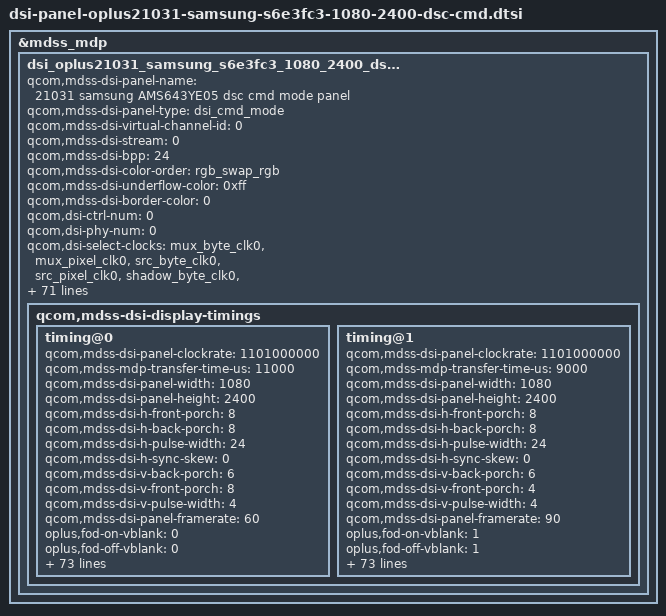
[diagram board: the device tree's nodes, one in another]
&mdss_mdp {
	dsi_oplus21031_samsung_s6e3fc3_1080_2400_dsc_cmd: qcom,mdss_dsi_oplus21031_samsung_s6e3fc3_1080_2400_dsc_cmd {
		qcom,mdss-dsi-panel-name =
		  "21031 samsung AMS643YE05 dsc cmd mode panel";
		qcom,mdss-dsi-panel-type = "dsi_cmd_mode";
		qcom,mdss-dsi-virtual-channel-id = <0>;
		qcom,mdss-dsi-stream = <0>;
		qcom,mdss-dsi-bpp = <24>;
		qcom,mdss-dsi-color-order = "rgb_swap_rgb";
		qcom,mdss-dsi-underflow-color = <0xff>;
		qcom,mdss-dsi-border-color = <0>;

		qcom,dsi-ctrl-num = <0>;
		qcom,dsi-phy-num = <0>;
		qcom,dsi-select-clocks = "src_byte_clk0", "src_pixel_clk0";

		qcom,mdss-dsi-traffic-mode = "non_burst_sync_event";
		qcom,mdss-dsi-lane-map = "lane_map_0123";
		qcom,mdss-dsi-bllp-eof-power-mode;
		qcom,mdss-dsi-bllp-power-mode;
		qcom,mdss-dsi-lane-0-state;
		qcom,mdss-dsi-lane-1-state;
		qcom,mdss-dsi-lane-2-state;
		qcom,mdss-dsi-lane-3-state;
		qcom,mdss-dsi-dma-trigger = "trigger_sw";
		qcom,mdss-dsi-mdp-trigger = "none";
		qcom,mdss-dsi-reset-sequence = <1 10>, <0 10>, <1 10>;
		qcom,mdss-dsi-te-pin-select = <1>;
		qcom,mdss-dsi-te-dcs-command = <1>;
		qcom,mdss-dsi-te-check-enable;
		qcom,mdss-dsi-te-using-te-pin;
		qcom,mdss-dsi-wr-mem-start = <0x2c>;
		qcom,mdss-dsi-wr-mem-continue = <0x3c>;
		qcom,mdss-dsi-panel-hdr-enabled;
		qcom,mdss-dsi-panel-hdr-color-primaries = <15000 15500 34000
			16000 13250 34500 7500 3000>;
		qcom,mdss-dsi-panel-peak-brightness = <4300000>;
		qcom,mdss-dsi-panel-blackness-level = <1023>;
		qcom,mdss-pan-physical-width-dimension = <68>;
		qcom,mdss-pan-physical-height-dimension = <152>;
		qcom,esd-check-enabled;
		qcom,mdss-dsi-panel-status-check-mode = "reg_read";
		qcom,mdss-dsi-panel-status-command = [06 01 00 01 05 00 02 0A 00];
		qcom,mdss-dsi-panel-status-command-state = "dsi_hs_mode";
		qcom,mdss-dsi-panel-status-value = <0x9F>;
		qcom,mdss-dsi-panel-status-read-length = <1>;

		qcom,mdss-dsi-display-timings {
			timing@0{
				qcom,mdss-dsi-panel-clockrate = <1101000000>;
				qcom,mdss-mdp-transfer-time-us = <11000>;
				qcom,mdss-dsi-panel-width = <1080>;
				qcom,mdss-dsi-panel-height = <2400>;
				qcom,mdss-dsi-h-front-porch = <8>;
				qcom,mdss-dsi-h-back-porch = <8>;
				qcom,mdss-dsi-h-pulse-width = <24>;
				qcom,mdss-dsi-h-sync-skew = <0>;
				qcom,mdss-dsi-v-back-porch = <6>;
				qcom,mdss-dsi-v-front-porch = <8>;
				qcom,mdss-dsi-v-pulse-width = <4>;
				qcom,mdss-dsi-panel-framerate = <60>;
				oplus,fod-on-vblank = <0>;
				oplus,fod-off-vblank = <0>;
				/* Apollo vsync config, need to measure TE signal */
				oplus,apollo-panel-vsync-width = <5680>;
				oplus,apollo-panel-vsync-period = <16850>;

				qcom,mdss-dsi-on-command = [
					/* PPS Setting */
					39 01 00 00 00 00 81 9E
						11 00 00 89 30 80 09 60
						04 38 00 1E 02 1C 02 1C
						02 00 02 0E 00 20 02 E3
						00 07 00 0C 03 50 03 64
						18 00 10 F0 03 0C 20 00
						06 0B 0B 33 0E 1C 2A 38
						46 54 62 69 70 77 79 7B
						7D 7E 01 02 01 00 09 40
						09 BE 19 FC 19 FA 19 F8
						1A 38 1A 78 1A B6 2A F6
						2B 34 2B 74 3B 74 6B F4
						00 00 00 00 00 00 00 00
						00 00 00 00 00 00 00 00
						00 00 00 00 00 00 00 00
						00 00 00 00 00 00 00 00
						00 00 00 00 00 00 00 00
					15 01 00 00 00 00 02 C2 14
					15 01 00 00 00 00 02 9D 01
					/* Display On Setting */
					05 01 00 00 78 00 01 11
					/* TE vsync ON */
					15 01 00 00 00 00 02 35 00
					/* CASET/PASET Setting */
					39 01 00 00 00 00 05 2A 00 00 04 37
					39 01 00 00 00 00 05 2B 00 00 09 5F
					/* FQ CON Setting*/
					39 00 00 00 00 00 03 F0 5A 5A
					39 00 00 00 00 00 03 B0 27 F2
					15 00 00 00 00 00 02 F2 00
					39 01 00 00 00 00 03 F0 A5 A5
					/* Freuency Setting */
					39 00 00 00 00 00 03 F0 5A 5A
					39 00 00 00 00 00 03 60 00 00	// 60Hz
					15 00 00 00 00 00 02 F7 0F
					39 01 00 00 00 00 03 F0 A5 A5
					/* FFC Setting: OSC 167MHz */
					39 00 00 00 00 00 03 F0 5A 5A
					39 00 00 00 00 00 03 FC 5A 5A
					39 00 00 00 00 00 03 B0 66 C5
					39 00 00 00 00 00 03 C5 00 8C
					39 00 00 00 00 00 03 B0 2A C5
					39 00 00 00 00 00 05 C5 0D 10 80 45
					39 00 00 00 00 00 03 B0 3E C5
					39 00 00 00 00 00 03 C5 4D A6
					39 00 00 00 00 00 03 F0 A5 A5
					39 01 00 00 00 00 03 FC A5 A5
					15 01 00 00 00 00 02 53 20
				];
				qcom,mdss-dsi-post-on-backlight = [
					/* Display On*/
					05 01 00 00 00 00 01 29
				];
				qcom,mdss-dsi-timing-switch-command = [
					/* 60hz Transition */
					39 00 00 00 00 00 03 F0 5A 5A
					39 00 00 00 00 00 03 60 00 00
					39 00 00 00 00 00 02 F7 0F
					39 01 00 00 00 00 03 F0 A5 A5
				];
				qcom,mdss-dsi-off-command = [
					05 01 00 00 0A 00 01 28
					05 01 00 00 78 00 01 10
				];
				qcom,mdss-dsi-lp1-command = [
					05 01 00 00 25 00 01 28
					39 00 00 00 00 00 03 F0 5A 5A
					39 00 00 00 00 00 02 91 01
					15 00 00 00 00 00 02 53 24
					15 00 00 00 00 00 02 BB 1D
					39 01 00 00 00 00 03 F0 A5 A5
				];
				qcom,mdss-dsi-nolp-command = [
					/* AOD CTRL setting */
					39 00 00 00 00 00 03 F0 5A 5A
					39 00 00 00 00 00 05 BB 11 0C 50 10
					39 01 00 00 00 00 03 F0 A5 A5
					/* AOD off */
					39 00 00 00 00 00 03 F0 5A 5A
					39 00 00 00 00 00 02 91 02
					15 00 00 00 00 00 02 53 20
					39 01 00 00 00 00 03 F0 A5 A5
				];
				qcom,mdss-dsi-aod-high-mode-command = [
					15 01 00 00 00 00 02 53 24
				];
				qcom,mdss-dsi-aod-low-mode-command = [
					15 01 00 00 00 00 02 53 24
				];
				qcom,mdss-dsi-aod-hbm-on-command = [
					/* AOD CTRL setting */
					39 00 00 00 00 00 03 F0 5A 5A
					39 00 00 00 00 00 05 BB 11 0C 50 10
					39 01 00 00 00 00 03 F0 A5 A5
					/* AOD off */
					39 00 00 00 00 00 03 F0 5A 5A
					39 00 00 00 00 00 02 91 02
					15 00 00 00 00 00 02 53 20
					39 01 00 00 00 00 03 F0 A5 A5
					/*ELVSS DIMING OFF,DLY OFF*/
					39 00 00 00 00 00 03 F0 5A 5A
					39 00 00 00 00 00 03 B0 91 63
					15 00 00 00 00 00 02 63 20
					39 01 00 00 00 00 03 F0 A5 A5
					/* HBM Mode ON */
					39 00 00 00 00 00 02 53 E0
					39 01 00 00 00 00 03 51 0F FF
				];
				qcom,mdss-dsi-hbm-on-command = [
					/*ELVSS DIMING OFF,DLY OFF*/
					39 00 00 00 00 00 03 F0 5A 5A
					39 00 00 00 00 00 03 B0 91 63
					15 00 00 00 00 00 02 63 20
					39 01 00 00 00 00 03 F0 A5 A5
					39 01 00 00 00 00 02 53 E0
					39 01 00 00 00 00 03 51 0F FF
				];
				qcom,mdss-dsi-normal-hbm-on-command = [
					39 01 00 00 00 00 02 53 E0
					39 01 00 00 00 00 03 51 0F FF
				];
				qcom,mdss-dsi-hbm-off-command = [
					/*ELVSS DIMING OFF,DLY OFF*/
					39 00 00 00 00 00 03 F0 5A 5A
					39 00 00 00 00 00 03 B0 91 63
					15 00 00 00 00 00 02 63 20
					39 01 00 00 00 00 03 F0 A5 A5
					15 01 00 00 00 00 02 53 20
				];
				qcom,mdss-dsi-aod-hbm-off-command = [
					/*HBM OFF */
					15 01 00 00 00 00 02 53 20
					/*AOD on */
					39 00 00 00 00 00 03 F0 5A 5A
					39 00 00 00 00 00 02 91 01
					15 00 00 00 00 00 02 53 24
					15 00 00 00 00 00 02 BB 1D
					39 01 00 00 00 00 03 F0 A5 A5
				];
				qcom,mdss-dsi-seed-off-command = [
					/* CRC OFF */
					39 00 00 00 00 00 03 F0 5A 5A
					15 00 00 00 00 00 02 5D 00
					39 00 00 00 00 00 02 62 01
					39 01 00 00 00 00 03 F0 A5 A5
				];
				qcom,mdss-dsi-seed-0-command = [
					/* SEED CRC Setting */
					39 00 00 00 00 00 03 F0 5A 5A
					39 00 00 00 00 00 02 5D 86
					/* SEED CRC ON */
					39 00 00 00 00 00 02 62 00
					/* SEED CRC DCI-P3 */
					39 00 00 00 00 00 03 B0 2B 62
					39 00 00 00 00 00 16 62 D8 00 04 00 FF 02 00 00 FF 18 FF E4 FB 00 F0 F6 EA 01 FF FF FF
					39 01 00 00 00 00 03 F0 A5 A5
				];
				qcom,mdss-dsi-seed-1-command = [
					/* SEED CRC Setting */
					39 00 00 00 00 00 03 F0 5A 5A
					39 00 00 00 00 00 02 5D 06
					/* SEED CRC ON */
					39 00 00 00 00 00 02 62 00
					/* SEED CRC sRGB */
					39 00 00 00 00 00 03 B0 01 62
					39 00 00 00 00 00 16 62 B0 02 06 3A D7 17 07 05 B2 48 F2 DC C4 07 C8 E9 E9 1D FF FF FF
					39 01 00 00 00 00 03 F0 A5 A5
				];
				qcom,mdss-dsi-seed-2-command = [
					/* SEED CRC Setting */
					39 00 00 00 00 00 03 F0 5A 5A
					39 00 00 00 00 00 02 5D 46
					/* SEED CRC ON */
					39 00 00 00 00 00 02 62 00
					/* SEED CRC Adobe */
					39 00 00 00 00 00 03 B0 16 62
					39 00 00 00 00 00 16 62 D8 00 04 00 FF 02 00 00 FF 18 FF E4 FB 00 F0 F6 EA 01 FF FF FF
					39 01 00 00 00 00 03 F0 A5 A5
				];
				qcom,mdss-dsi-osc-clk-mode0-command = [
					/* OSC 167MHz */
					39 00 00 00 00 00 03 F0 5A 5A
					39 00 00 00 00 00 03 FC 5A 5A
					39 00 00 00 00 00 03 B0 66 C5
					39 00 00 00 00 00 03 C5 00 8C
					39 00 00 00 00 00 03 B0 2A C5
					39 00 00 00 00 00 05 C5 0D 10 80 45
					39 00 00 00 00 00 03 B0 3E C5
					39 00 00 00 00 00 03 C5 4D A6
					39 00 00 00 00 00 03 F0 A5 A5
					39 01 00 00 00 00 03 FC A5 A5
				];
				qcom,mdss-dsi-osc-clk-mode1-command = [
					/* OSC 169MHz */
					39 00 00 00 00 00 03 F0 5A 5A
					39 00 00 00 00 00 03 FC 5A 5A
					39 00 00 00 00 00 03 B0 66 C5
					39 00 00 00 00 00 03 C5 00 8C
					39 00 00 00 00 00 03 B0 2A C5
					39 00 00 00 00 00 05 C5 0D 10 80 45
					39 00 00 00 00 00 03 B0 3E C5
					39 00 00 00 00 00 03 C5 4E 97
					39 00 00 00 00 00 03 F0 A5 A5
					39 01 00 00 00 00 03 FC A5 A5
				];
				qcom,mdss-dsi-hbm-enter-switch-command = [
					39 00 00 00 00 00 03 F0 5A 5A
					39 00 00 00 00 00 03 B0 02 90
					39 00 00 00 00 00 02 90 14
					39 00 00 00 00 00 02 53 E0
					39 01 00 00 00 00 03 F0 A5 A5
				];
				qcom,mdss-dsi-hbm-exit-switch-command = [
					39 00 00 00 00 00 03 F0 5A 5A
					39 00 00 00 00 00 03 B0 02 90
					39 00 00 00 00 00 02 90 1C
					39 00 00 00 00 00 02 53 20
					39 01 00 00 00 00 03 F0 A5 A5
				];
				qcom,mdss-dsi-aod-hbm-on-command-state = "dsi_hs_mode";
				qcom,mdss-dsi-aod-hbm-off-command-state = "dsi_hs_mode";
				qcom,mdss-dsi-seed-off-command-state = "dsi_hs_mode";
				qcom,mdss-dsi-seed-0-command-state = "dsi_hs_mode";
				qcom,mdss-dsi-seed-1-command-state = "dsi_hs_mode";
				qcom,mdss-dsi-seed-2-command-state = "dsi_hs_mode";
				qcom,mdss-dsi-lp1-command-state = "dsi_hs_mode";
				qcom,mdss-dsi-nolp-command-state = "dsi_hs_mode";
				qcom,mdss-dsi-post-on-backlight-state = "dsi_hs_mode";
				qcom,mdss-dsi-on-command-state = "dsi_hs_mode";
				qcom,mdss-dsi-off-command-state = "dsi_hs_mode";
				qcom,compression-mode = "dsc";
				qcom,mdss-dsc-slice-height = <30>;
				qcom,mdss-dsc-slice-width = <540>;
				qcom,mdss-dsc-slice-per-pkt = <2>;
				qcom,mdss-dsc-bit-per-component = <8>;
				qcom,mdss-dsc-bit-per-pixel = <8>;
				qcom,mdss-dsc-block-prediction-enable;
			};

			timing@1{
				qcom,mdss-dsi-panel-clockrate = <1101000000>;
				qcom,mdss-mdp-transfer-time-us = <9000>;
				qcom,mdss-dsi-panel-width = <1080>;
				qcom,mdss-dsi-panel-height = <2400>;
				qcom,mdss-dsi-h-front-porch = <8>;
				qcom,mdss-dsi-h-back-porch = <8>;
				qcom,mdss-dsi-h-pulse-width = <24>;
				qcom,mdss-dsi-h-sync-skew = <0>;
				qcom,mdss-dsi-v-back-porch = <6>;
				qcom,mdss-dsi-v-front-porch = <4>;
				qcom,mdss-dsi-v-pulse-width = <4>;
				qcom,mdss-dsi-panel-framerate = <90>;
				oplus,fod-on-vblank = <1>;
				oplus,fod-off-vblank = <1>;
				/* Apollo vsync config, need to measure TE signal */
				oplus,apollo-panel-vsync-width = <70>;
				oplus,apollo-panel-vsync-period = <11250>;
				qcom,mdss-dsi-on-command = [
					/* PPS Setting */
					39 01 00 00 00 00 81 9E
						11 00 00 89 30 80 09 60
						04 38 00 1E 02 1C 02 1C
						02 00 02 0E 00 20 02 E3
						00 07 00 0C 03 50 03 64
						18 00 10 F0 03 0C 20 00
						06 0B 0B 33 0E 1C 2A 38
						46 54 62 69 70 77 79 7B
						7D 7E 01 02 01 00 09 40
						09 BE 19 FC 19 FA 19 F8
						1A 38 1A 78 1A B6 2A F6
						2B 34 2B 74 3B 74 6B F4
						00 00 00 00 00 00 00 00
						00 00 00 00 00 00 00 00
						00 00 00 00 00 00 00 00
						00 00 00 00 00 00 00 00
						00 00 00 00 00 00 00 00
					15 01 00 00 00 00 02 C2 14
					15 01 00 00 00 00 02 9D 01
					/* Display On Setting */
					05 01 00 00 78 00 01 11
					/* TE vsync ON */
					15 01 00 00 00 00 02 35 00
					/* CASET/PASET Setting */
					39 01 00 00 00 00 05 2A 00 00 04 37
					39 01 00 00 00 00 05 2B 00 00 09 5F
					/* FQ CON Setting*/
					39 00 00 00 00 00 03 F0 5A 5A
					39 00 00 00 00 00 03 B0 27 F2
					15 00 00 00 00 00 02 F2 00
					39 01 00 00 00 00 03 F0 A5 A5
					/* Freuency Setting */
					39 00 00 00 00 00 03 F0 5A 5A
					39 00 00 00 00 00 03 60 08 00	// 90Hz
					39 00 00 00 00 00 02 F7 0F
					39 01 00 00 00 00 03 F0 A5 A5
					/* FFC Setting: OSC 167MHz */
					39 00 00 00 00 00 03 F0 5A 5A
					39 00 00 00 00 00 03 FC 5A 5A
					39 00 00 00 00 00 03 B0 66 C5
					39 00 00 00 00 00 03 C5 00 8C
					39 00 00 00 00 00 03 B0 2A C5
					39 00 00 00 00 00 05 C5 0D 10 80 45
					39 00 00 00 00 00 03 B0 3E C5
					39 00 00 00 00 00 03 C5 4D A6
					39 00 00 00 00 00 03 F0 A5 A5
					39 01 00 00 00 00 03 FC A5 A5
					15 01 00 00 00 00 02 53 20
				];
				qcom,mdss-dsi-post-on-backlight = [
					/* Display On*/
					05 01 00 00 00 00 01 29
				];
				qcom,mdss-dsi-timing-switch-command = [
					/* 90hz Transition */
					39 00 00 00 00 00 03 F0 5A 5A
					39 00 00 00 00 00 03 60 08 00
					39 00 00 00 00 00 02 F7 0F
					39 01 00 00 00 00 03 F0 A5 A5
				];
				qcom,mdss-dsi-off-command = [
					05 01 00 00 0A 00 01 28
					05 01 00 00 78 00 01 10
				];
				qcom,mdss-dsi-lp1-command = [
					05 01 00 00 25 00 01 28
					39 00 00 00 00 00 03 F0 5A 5A
					39 00 00 00 00 00 02 91 01
					15 00 00 00 00 00 02 53 24
					15 00 00 00 00 00 02 BB 1D
					39 01 00 00 00 00 03 F0 A5 A5
				];
				qcom,mdss-dsi-nolp-command = [
					/* AOD CTRL setting */
					39 00 00 00 00 00 03 F0 5A 5A
					39 00 00 00 00 00 05 BB 11 0C 50 10
					39 01 00 00 00 00 03 F0 A5 A5
					/* AOD off */
					39 00 00 00 00 00 03 F0 5A 5A
					39 00 00 00 00 00 02 91 02
					15 00 00 00 00 00 02 53 20
					39 01 00 00 00 00 03 F0 A5 A5
				];
				qcom,mdss-dsi-aod-high-mode-command = [
					15 01 00 00 00 00 02 53 24
				];
				qcom,mdss-dsi-aod-low-mode-command = [
					15 01 00 00 00 00 02 53 24
				];
				qcom,mdss-dsi-aod-hbm-on-command = [
					/* AOD CTRL setting */
					39 00 00 00 00 00 03 F0 5A 5A
					39 00 00 00 00 00 05 BB 11 0C 50 10
					39 01 00 00 00 00 03 F0 A5 A5
					/* AOD off */
					39 00 00 00 00 00 03 F0 5A 5A
					39 00 00 00 00 00 02 91 02
					15 00 00 00 00 00 02 53 20
					39 01 00 00 00 00 03 F0 A5 A5
					/*ELVSS DIMING OFF,DLY OFF*/
					39 00 00 00 00 00 03 F0 5A 5A
					39 00 00 00 00 00 03 B0 91 63
					15 00 00 00 00 00 02 63 20
					39 01 00 00 00 00 03 F0 A5 A5
					/* HBM Mode ON */
					39 00 00 00 00 00 02 53 E0
					39 01 00 00 00 00 03 51 0F FF
				];
				qcom,mdss-dsi-hbm-on-command = [
					/*ELVSS DIMING OFF,DLY OFF*/
					39 00 00 00 05 00 03 F0 5A 5A
					39 00 00 00 00 00 03 B0 91 63
					15 00 00 00 00 00 02 63 20
					39 01 00 00 00 00 03 F0 A5 A5
					39 01 00 00 00 00 02 53 E0
					39 01 00 00 00 00 03 51 0F FF
				];
				qcom,mdss-dsi-normal-hbm-on-command = [
					39 01 00 00 00 00 02 53 E0
					39 01 00 00 00 00 03 51 0F FF
				];
				qcom,mdss-dsi-hbm-off-command = [
					/*ELVSS DIMING OFF,DLY OFF*/
					39 00 00 00 00 00 03 F0 5A 5A
					39 00 00 00 00 00 03 B0 91 63
					15 00 00 00 00 00 02 63 20
					39 01 00 00 00 00 03 F0 A5 A5
					15 01 00 00 00 00 02 53 20
				];
				qcom,mdss-dsi-aod-hbm-off-command = [
					/*HBM OFF */
					15 01 00 00 00 00 02 53 20
					/*AOD on */
					39 00 00 00 00 00 03 F0 5A 5A
					39 00 00 00 00 00 02 91 01
					15 00 00 00 00 00 02 53 24
					15 00 00 00 00 00 02 BB 1D
					39 01 00 00 00 00 03 F0 A5 A5
				];
				qcom,mdss-dsi-seed-off-command = [
					/* CRC OFF */
					39 00 00 00 00 00 03 F0 5A 5A
					15 00 00 00 00 00 02 5D 00
					39 00 00 00 00 00 02 62 01
					39 01 00 00 00 00 03 F0 A5 A5
				];
				qcom,mdss-dsi-seed-0-command = [
					/* SEED CRC Setting */
					39 00 00 00 00 00 03 F0 5A 5A
					39 00 00 00 00 00 02 5D 86
					/* SEED CRC ON */
					39 00 00 00 00 00 02 62 00
					/* SEED CRC DCI-P3 */
					39 00 00 00 00 00 03 B0 2B 62
					39 00 00 00 00 00 16 62 D8 00 04 00 FF 02 00 00 FF 18 FF E4 FB 00 F0 F6 EA 01 FF FF FF
					39 01 00 00 00 00 03 F0 A5 A5
				];
				qcom,mdss-dsi-seed-1-command = [
					/* SEED CRC Setting */
					39 00 00 00 00 00 03 F0 5A 5A
					39 00 00 00 00 00 02 5D 06
					/* SEED CRC ON */
					39 00 00 00 00 00 02 62 00
					/* SEED CRC sRGB */
					39 00 00 00 00 00 03 B0 01 62
					39 00 00 00 00 00 16 62 B0 02 06 3A D7 17 07 05 B2 48 F2 DC C4 07 C8 E9 E9 1D FF FF FF
					39 01 00 00 00 00 03 F0 A5 A5
				];
				qcom,mdss-dsi-seed-2-command = [
					/* SEED CRC Setting */
					39 00 00 00 00 00 03 F0 5A 5A
					39 00 00 00 00 00 02 5D 46
					/* SEED CRC ON */
					39 00 00 00 00 00 02 62 00
					/* SEED CRC Adobe */
					39 00 00 00 00 00 03 B0 16 62
					39 00 00 00 00 00 16 62 D8 00 04 00 FF 02 00 00 FF 18 FF E4 FB 00 F0 F6 EA 01 FF FF FF
					39 01 00 00 00 00 03 F0 A5 A5
				];
				qcom,mdss-dsi-osc-clk-mode0-command = [
					/* OSC 167MHz */
					39 00 00 00 00 00 03 F0 5A 5A
					39 00 00 00 00 00 03 FC 5A 5A
					39 00 00 00 00 00 03 B0 66 C5
					39 00 00 00 00 00 03 C5 00 8C
					39 00 00 00 00 00 03 B0 2A C5
					39 00 00 00 00 00 05 C5 0D 10 80 45
					39 00 00 00 00 00 03 B0 3E C5
					39 00 00 00 00 00 03 C5 4D A6
					39 00 00 00 00 00 03 F0 A5 A5
					39 01 00 00 00 00 03 FC A5 A5
				];
				qcom,mdss-dsi-osc-clk-mode1-command = [
					/* OSC 169MHz */
					39 00 00 00 00 00 03 F0 5A 5A
					39 00 00 00 00 00 03 FC 5A 5A
					39 00 00 00 00 00 03 B0 66 C5
					39 00 00 00 00 00 03 C5 00 8C
					39 00 00 00 00 00 03 B0 2A C5
					39 00 00 00 00 00 05 C5 0D 10 80 45
					39 00 00 00 00 00 03 B0 3E C5
					39 00 00 00 00 00 03 C5 4E 97
					39 00 00 00 00 00 03 F0 A5 A5
					39 01 00 00 00 00 03 FC A5 A5
				];
				qcom,mdss-dsi-hbm-enter-switch-command = [
					39 00 00 00 00 00 03 F0 5A 5A
					39 00 00 00 00 00 03 B0 02 90
					39 00 00 00 00 00 02 90 14
					39 00 00 00 00 00 02 53 E0
					39 01 00 00 00 00 03 F0 A5 A5
				];
				qcom,mdss-dsi-hbm-exit-switch-command = [
					39 00 00 00 00 00 03 F0 5A 5A
					39 00 00 00 00 00 03 B0 02 90
					39 00 00 00 00 00 02 90 1C
					39 00 00 00 00 00 02 53 20
					39 01 00 00 00 00 03 F0 A5 A5
				];

				qcom,mdss-dsi-aod-hbm-on-command-state = "dsi_hs_mode";
				qcom,mdss-dsi-aod-hbm-off-command-state = "dsi_hs_mode";
				qcom,mdss-dsi-seed-off-command-state = "dsi_hs_mode";
				qcom,mdss-dsi-seed-0-command-state = "dsi_hs_mode";
				qcom,mdss-dsi-seed-1-command-state = "dsi_hs_mode";
				qcom,mdss-dsi-seed-2-command-state = "dsi_hs_mode";
				qcom,mdss-dsi-lp1-command-state = "dsi_hs_mode";
				qcom,mdss-dsi-nolp-command-state = "dsi_hs_mode";
				qcom,mdss-dsi-post-on-backlight-state = "dsi_hs_mode";
				qcom,mdss-dsi-on-command-state = "dsi_hs_mode";
				qcom,mdss-dsi-off-command-state = "dsi_hs_mode";
				qcom,compression-mode = "dsc";
				qcom,mdss-dsc-slice-height = <30>;
				qcom,mdss-dsc-slice-width = <540>;
				qcom,mdss-dsc-slice-per-pkt = <2>;
				qcom,mdss-dsc-bit-per-component = <8>;
				qcom,mdss-dsc-bit-per-pixel = <8>;
				qcom,mdss-dsc-block-prediction-enable;
			};
		};
	};
};

&dsi_oplus21031_samsung_s6e3fc3_1080_2400_dsc_cmd {
	qcom,panel-supply-entries = <&dsi_panel_pwr_supply_vout>;
	qcom,mdss-dsi-bl-pmic-control-type = "bl_ctrl_dcs";
	qcom,mdss-dsi-bl-min-level = <1>;
	qcom,mdss-dsi-bl-max-level = <4095>;
	qcom,mdss-brightness-max-level = <4095>;
	qcom,mdss-dsi-bl-normal-max-level = <2047>;
	qcom,mdss-brightness-normal-max-level = <2047>;
	qcom,mdss-brightness-default-level = <400>;
	qcom,mdss-dsi-bl-hbm-min-level = <3327>;
	qcom,platform-te-gpio = <&tlmm 80 0>;
	qcom,platform-reset-gpio = <&tlmm 44 0>;
	oplus,mdss-dsi-vendor-name = "AMS643YE01";
	oplus,mdss-dsi-manufacture = "samsung1024";
	oplus,osc-support;
	oplus,mdss-dsi-osc-clk-mode0-rate = <167000>;
	oplus,mdss-dsi-osc-clk-mode1-rate = <169000>;
	oplus,dsi-fod-brightness = <0 0xff>,
				<4 0xEC>,
				<6 0xEB>,
				<8 0xEB>,
				<10 0xEA>,
				<20 0xE4>,
				<40 0xDB>,
				<60 0xD4>,
				<90 0xCB>,
				<140 0xC0>,
				<200 0xB4>,
				<300 0xA5>,
				<450 0x92>,
				<600 0x82>,
				<800 0x6E>,
				<1000 0x61>,
				<1200 0x53>,
				<1400 0x48>,
				<1600 0x3B>,
				<1800 0x2F>,
				<2047 0x22>;
	oplus,esd-check-flag-enabled;
	qcom,esd-check-enabled;
	qcom,mdss-dsi-panel-status-check-mode = "reg_read";
	qcom,mdss-dsi-panel-status-command = [
		06 01 00 01 05 00 01 0A
		06 01 00 01 05 00 01 0E
		06 01 00 01 05 00 01 05
	];
	qcom,mdss-dsi-panel-status-command-state = "dsi_lp_mode";
	qcom,mdss-dsi-panel-status-value = <0x9F 0x80 0x00>;
	qcom,mdss-dsi-panel-status-read-length = <1 1 1>;

	qcom,ulps-enabled;
	qcom,dsi-select-clocks = "mux_byte_clk0", "mux_pixel_clk0",
				"src_byte_clk0", "src_pixel_clk0",
				"shadow_byte_clk0", "shadow_pixel_clk0";

	qcom,mdss-dsi-display-timings {
		timing@0{
			qcom,mdss-dsi-panel-phy-timings = [00 24 0A 0A 1A 24 0A
				0A 07 02 04 00 1D 0F];
			qcom,display-topology = <1 1 1>;
			qcom,default-topology-index = <0>;
		};
		timing@1{
			qcom,mdss-dsi-panel-phy-timings = [00 24 0A 0A 1A 24 0A
				0A 07 02 04 00 1D 0F];
			qcom,display-topology = <1 1 1>;
			qcom,default-topology-index = <0>;
		};
	};
};

&dsi_oplus21031_samsung_s6e3fc3_1080_2400_dsc_cmd {
	oplus,apollo_backlight_enable;
	oplus,apollo-sync-brightness-level = <203>;
};

&dsi_oplus21031_samsung_s6e3fc3_1080_2400_dsc_cmd {
	qcom,panel_voltage_vddi_name = "vddi";
	qcom,panel_voltage_vddi = <0 1650000 1800000 1950000>;
	qcom,panel_voltage_vddr_name = "vddr";
	qcom,panel_voltage_vddr = <1 1450000 1500000 1600000>;
};

&dsi_oplus21031_samsung_s6e3fc3_1080_2400_dsc_cmd {
	pxlw,soft-iris-enable;
};
